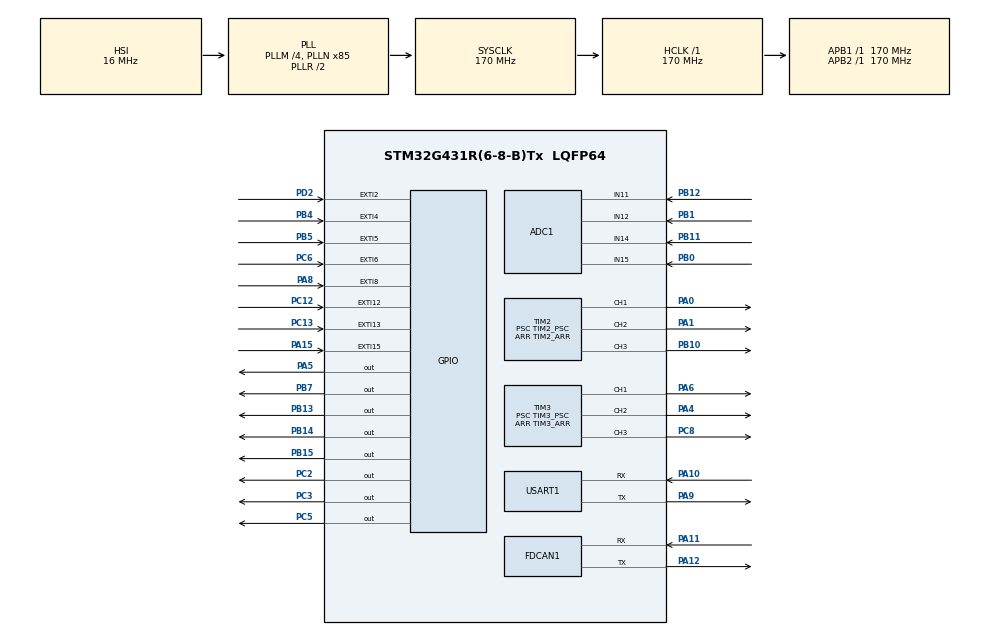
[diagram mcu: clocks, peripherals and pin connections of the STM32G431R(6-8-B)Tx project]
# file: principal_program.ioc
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ADC1.Channel-0\#ChannelRegularConversion=ADC_CHANNEL_11
ADC1.Channel-1\#ChannelRegularConversion=ADC_CHANNEL_12
ADC1.Channel-2\#ChannelRegularConversion=ADC_CHANNEL_14
ADC1.Channel-3\#ChannelRegularConversion=ADC_CHANNEL_15
ADC1.ContinuousConvMode=ENABLE
ADC1.DMAContinuousRequests=ENABLE
ADC1.NbrOfConversion=4
ADC1.NbrOfConversionFlag=1
ADC1.OffsetNumber-0\#ChannelRegularConversion=ADC_OFFSET_NONE
ADC1.OffsetNumber-1\#ChannelRegularConversion=ADC_OFFSET_NONE
ADC1.OffsetNumber-2\#ChannelRegularConversion=ADC_OFFSET_NONE
ADC1.OffsetNumber-3\#ChannelRegularConversion=ADC_OFFSET_NONE
ADC1.Rank-0\#ChannelRegularConversion=1
ADC1.Rank-1\#ChannelRegularConversion=2
ADC1.Rank-2\#ChannelRegularConversion=3
ADC1.Rank-3\#ChannelRegularConversion=4
ADC1.SamplingTime-0\#ChannelRegularConversion=ADC_SAMPLETIME_2CYCLES_5
ADC1.SamplingTime-1\#ChannelRegularConversion=ADC_SAMPLETIME_2CYCLES_5
ADC1.SamplingTime-2\#ChannelRegularConversion=ADC_SAMPLETIME_2CYCLES_5
ADC1.SamplingTime-3\#ChannelRegularConversion=ADC_SAMPLETIME_2CYCLES_5
ADC1.master=1
Dma.ADC1.0.Direction=DMA_PERIPH_TO_MEMORY
Dma.ADC1.0.EventEnable=DISABLE
Dma.ADC1.0.Instance=DMA1_Channel1
Dma.ADC1.0.MemDataAlignment=DMA_MDATAALIGN_HALFWORD
Dma.ADC1.0.MemInc=DMA_MINC_ENABLE
Dma.ADC1.0.Mode=DMA_CIRCULAR
Dma.ADC1.0.PeriphDataAlignment=DMA_PDATAALIGN_HALFWORD
Dma.ADC1.0.PeriphInc=DMA_PINC_DISABLE
Dma.ADC1.0.Polarity=HAL_DMAMUX_REQ_GEN_RISING
Dma.ADC1.0.Priority=DMA_PRIORITY_MEDIUM
Dma.ADC1.0.RequestNumber=1
Dma.ADC1.0.SignalID=NONE
Dma.ADC1.0.SyncEnable=DISABLE
Dma.ADC1.0.SyncPolarity=HAL_DMAMUX_SYNC_NO_EVENT
Dma.ADC1.0.SyncRequestNumber=1
Dma.ADC1.0.SyncSignalID=NONE
Dma.Request0=ADC1
Dma.Request1=USART1_TX
Dma.Request2=USART1_RX
Dma.USART1_RX.2.Direction=DMA_PERIPH_TO_MEMORY
Dma.USART1_RX.2.EventEnable=DISABLE
Dma.USART1_RX.2.Instance=DMA2_Channel2
Dma.USART1_RX.2.MemDataAlignment=DMA_MDATAALIGN_BYTE
Dma.USART1_RX.2.MemInc=DMA_MINC_ENABLE
Dma.USART1_RX.2.Mode=DMA_NORMAL
Dma.USART1_RX.2.PeriphDataAlignment=DMA_PDATAALIGN_BYTE
Dma.USART1_RX.2.PeriphInc=DMA_PINC_DISABLE
Dma.USART1_RX.2.Polarity=HAL_DMAMUX_REQ_GEN_RISING
Dma.USART1_RX.2.Priority=DMA_PRIORITY_LOW
Dma.USART1_RX.2.RequestNumber=1
Dma.USART1_RX.2.SignalID=NONE
Dma.USART1_RX.2.SyncEnable=DISABLE
Dma.USART1_RX.2.SyncPolarity=HAL_DMAMUX_SYNC_NO_EVENT
Dma.USART1_RX.2.SyncRequestNumber=1
Dma.USART1_RX.2.SyncSignalID=NONE
Dma.USART1_TX.1.Direction=DMA_MEMORY_TO_PERIPH
Dma.USART1_TX.1.EventEnable=DISABLE
Dma.USART1_TX.1.Instance=DMA2_Channel1
Dma.USART1_TX.1.MemDataAlignment=DMA_MDATAALIGN_BYTE
Dma.USART1_TX.1.MemInc=DMA_MINC_ENABLE
Dma.USART1_TX.1.Mode=DMA_NORMAL
Dma.USART1_TX.1.PeriphDataAlignment=DMA_PDATAALIGN_BYTE
Dma.USART1_TX.1.PeriphInc=DMA_PINC_DISABLE
Dma.USART1_TX.1.Polarity=HAL_DMAMUX_REQ_GEN_RISING
Dma.USART1_TX.1.Priority=DMA_PRIORITY_LOW
Dma.USART1_TX.1.RequestNumber=1
Dma.USART1_TX.1.SignalID=NONE
Dma.USART1_TX.1.SyncEnable=DISABLE
Dma.USART1_TX.1.SyncPolarity=HAL_DMAMUX_SYNC_NO_EVENT
Dma.USART1_TX.1.SyncRequestNumber=1
Dma.USART1_TX.1.SyncSignalID=NONE
FDCAN1.CalculateBaudRateNominal=499999
FDCAN1.CalculateTimeBitNominal=2000
FDCAN1.CalculateTimeQuantumNominal=117.64705882352942
FDCAN1.DataPrescaler=2
FDCAN1.DataTimeSeg1=14
FDCAN1.DataTimeSeg2=2
FDCAN1.FrameFormat=FDCAN_FRAME_CLASSIC
FDCAN1.Mode=FDCAN_MODE_NORMAL
FDCAN1.NominalPrescaler=20
FDCAN1.NominalTimeSeg1=14
FDCAN1.ProtocolException=ENABLE
FDCAN1.StdFiltersNbr=FDCAN_FILTER_COUNT
FDCAN1.TransmitPause=ENABLE
FREERTOS.Tasks01=defaultTask,24,256,StartDefaultTask,As weak,NULL,Dynamic,NULL,NULL;UartTask,40,256,StartUartTask,As weak,NULL,Dynamic,NULL,NULL;MotorTask,51,128,StartMotorTask,As weak,NULL,Dynamic,NULL,NULL;FdCanTask,41,256,StartFdCanTask,As weak,NULL,Dynamic,NULL,NULL;VehicleUpdateTa,49,128,StartVehicleUpdateTask,As weak,NULL,Dynamic,NULL,NULL;AdcTask,50,128,StartAdcTask,As weak,NULL,Dynamic,NULL,NULL;VehicleTask,48,256,StartVehicleTask,As weak,NULL,Dynamic,NULL,NULL
FREERTOS.configENABLE_BACKWARD_COMPATIBILITY=0
FREERTOS.configTOTAL_HEAP_SIZE=8192
FREERTOS.configUSE_NEWLIB_REENTRANT=1
Mcu.Family=STM32G4
Mcu.Name=STM32G431R(6-8-B)Tx
Mcu.Package=LQFP64
NUCLEO-G431RB.BUTTON=1
NUCLEO-G431RB.LD1=true
NUCLEO-G431RB.VCP=true
NVIC.DMA1_Channel1_IRQn=true\:5\:0\:false\:false\:true\:true\:false\:true\:true
NVIC.DMA2_Channel1_IRQn=true\:5\:0\:false\:false\:true\:false\:false\:true\:true
NVIC.DMA2_Channel2_IRQn=true\:5\:0\:false\:false\:true\:false\:false\:true\:true
NVIC.EXTI15_10_IRQn=true\:5\:0\:false\:false\:true\:true\:false\:true\:true
NVIC.EXTI2_IRQn=true\:5\:0\:false\:false\:true\:true\:true\:true\:true
NVIC.EXTI4_IRQn=true\:5\:0\:false\:false\:true\:true\:true\:true\:true
NVIC.EXTI9_5_IRQn=true\:5\:0\:false\:false\:true\:true\:true\:true\:true
NVIC.FDCAN1_IT0_IRQn=true\:5\:0\:false\:false\:true\:true\:true\:true\:true
NVIC.FDCAN1_IT1_IRQn=true\:5\:0\:false\:false\:true\:true\:true\:true\:true
NVIC.PriorityGroup=NVIC_PRIORITYGROUP_4
NVIC.TIM1_UP_TIM16_IRQn=true\:5\:0\:false\:false\:true\:true\:true\:true\:true
NVIC.TIM2_IRQn=true\:5\:0\:false\:false\:true\:true\:true\:true\:true
NVIC.TIM3_IRQn=true\:5\:0\:false\:false\:true\:true\:true\:true\:true
NVIC.TIM4_IRQn=true\:5\:0\:false\:false\:true\:true\:true\:true\:true
NVIC.TIM6_DAC_IRQn=true\:15\:0\:false\:false\:true\:false\:false\:true\:true
NVIC.TimeBase=TIM6_DAC_IRQn
NVIC.TimeBaseIP=TIM6
PA0.Signal=S_TIM2_CH1
PA1.Signal=S_TIM2_CH2
PA10.Mode=Asynchronous
PA10.Signal=USART1_RX
PA11.Mode=FDCAN_Activate
PA11.Signal=FDCAN1_RX
PA12.Mode=FDCAN_Activate
PA12.Signal=FDCAN1_TX
PA13.GPIO_Label=T_SWDIO
PA13.Signal=SYS_JTMS-SWDIO
PA14.GPIO_Label=T_SWCLK
PA14.Signal=SYS_JTCK-SWCLK
PA15.GPIO_ModeDefaultEXTI=GPIO_MODE_IT_RISING_FALLING
PA15.GPIO_PuPd=GPIO_NOPULL
PA15.Signal=GPXTI15
PA2.Signal=LPUART1_TX
PA3.Signal=LPUART1_RX
PA4.Signal=S_TIM3_CH2
PA5.Signal=GPIO_Output
PA6.Signal=S_TIM3_CH1
PA8.GPIO_ModeDefaultEXTI=GPIO_MODE_IT_RISING_FALLING
PA8.GPIO_PuPd=GPIO_NOPULL
PA8.Signal=GPXTI8
PA9.Mode=Asynchronous
PA9.Signal=USART1_TX
PB0.Mode=IN15-Single-Ended
PB0.Signal=ADC1_IN15
PB1.Mode=IN12-Single-Ended
PB1.Signal=ADC1_IN12
PB10.Signal=S_TIM2_CH3
PB11.Mode=IN14-Single-Ended
PB11.Signal=ADC1_IN14
PB12.Mode=IN11-Single-Ended
PB12.Signal=ADC1_IN11
PB13.GPIO_PuPd=GPIO_NOPULL
PB13.Signal=GPIO_Output
PB14.GPIO_PuPd=GPIO_NOPULL
PB14.Signal=GPIO_Output
PB15.GPIO_PuPd=GPIO_NOPULL
PB15.Signal=GPIO_Output
PB3.GPIO_Label=T_SWO
PB3.Signal=SYS_JTDO-SWO
PB4.GPIO_ModeDefaultEXTI=GPIO_MODE_IT_RISING_FALLING
PB4.GPIO_PuPd=GPIO_NOPULL
PB4.Signal=GPXTI4
PB5.GPIO_ModeDefaultEXTI=GPIO_MODE_IT_RISING_FALLING
PB5.GPIO_PuPd=GPIO_NOPULL
PB5.Signal=GPXTI5
PB7.GPIO_PuPd=GPIO_NOPULL
PB7.Signal=GPIO_Output
PC12.GPIO_ModeDefaultEXTI=GPIO_MODE_IT_RISING_FALLING
PC12.GPIO_PuPd=GPIO_NOPULL
PC12.Signal=GPXTI12
PC13.Signal=GPXTI13
PC14-OSC32_IN.GPIO_Label=RCC_OSC32_OUT
PC14-OSC32_IN.Signal=RCC_OSC32_IN
PC15-OSC32_OUT.GPIO_Label=RCC_OSC32_OUT
PC15-OSC32_OUT.Signal=RCC_OSC32_OUT
PC2.GPIO_PuPd=GPIO_NOPULL
PC2.Signal=GPIO_Output
PC3.GPIO_PuPd=GPIO_NOPULL
PC3.Signal=GPIO_Output
PC5.Signal=GPIO_Output
PC6.GPIO_ModeDefaultEXTI=GPIO_MODE_IT_FALLING
PC6.Signal=GPXTI6
PC8.Signal=S_TIM3_CH3
PD2.GPIO_ModeDefaultEXTI=GPIO_MODE_IT_RISING_FALLING
PD2.GPIO_PuPd=GPIO_NOPULL
PD2.Signal=GPXTI2
PF0-OSC_IN.GPIO_Label=RCC_OSC_IN
PF0-OSC_IN.Signal=RCC_OSC_IN
PF1-OSC_OUT.GPIO_Label=RCC_OSC_OUT
PF1-OSC_OUT.Signal=RCC_OSC_OUT
ProjectManager.HeapSize=0x200
ProjectManager.StackSize=0x400
ProjectManager.TargetToolchain=STM32CubeIDE
RCC.ADC12Freq_Value=170000000
RCC.AHBFreq_Value=170000000
RCC.APB1Freq_Value=170000000
RCC.APB1TimFreq_Value=170000000
RCC.APB2Freq_Value=170000000
RCC.APB2TimFreq_Value=170000000
RCC.CortexFreq_Value=170000000
RCC.EXTERNAL_CLOCK_VALUE=12288000
RCC.HCLKFreq_Value=170000000
RCC.HSE_VALUE=24000000
RCC.HSI48_VALUE=48000000
RCC.HSI_VALUE=16000000
RCC.LSE_VALUE=32768
RCC.PLLM=RCC_PLLM_DIV4
RCC.PLLN=85
RCC.RTCClockSelection=RCC_RTCCLKSOURCE_LSE
RCC.SYSCLKFreq_VALUE=170000000
RCC.SYSCLKSource=RCC_SYSCLKSOURCE_PLLCLK
RCC.USBFreq_Value=170000000
RCC.VCOOutputFreq_Value=340000000
SH.S_TIM2_CH1.0=TIM2_CH1,PWM Generation1 CH1
SH.S_TIM2_CH2.0=TIM2_CH2,PWM Generation2 CH2
SH.S_TIM2_CH3.0=TIM2_CH3,PWM Generation3 CH3
SH.S_TIM3_CH1.0=TIM3_CH1,PWM Generation1 CH1
SH.S_TIM3_CH2.0=TIM3_CH2,PWM Generation2 CH2
SH.S_TIM3_CH3.0=TIM3_CH3,PWM Generation3 CH3
TIM1.Channel-Output\ Compare1\ No\ Output=TIM_CHANNEL_1
TIM1.PeriodNoDither=TIM1_ARR
TIM1.Prescaler=TIM1_PSC
TIM2.Channel-PWM\ Generation1\ CH1=TIM_CHANNEL_1
TIM2.Channel-PWM\ Generation2\ CH2=TIM_CHANNEL_2
TIM2.Channel-PWM\ Generation3\ CH3=TIM_CHANNEL_3
TIM2.OCMode_PWM-PWM\ Generation3\ CH3=TIM_OCMODE_PWM1
TIM2.PeriodNoDither=TIM2_ARR
TIM2.Prescaler=TIM2_PSC
TIM2.PulseNoDither_1=0
TIM2.PulseNoDither_2=0
TIM2.PulseNoDither_3=0
TIM3.Channel-PWM\ Generation1\ CH1=TIM_CHANNEL_1
TIM3.Channel-PWM\ Generation2\ CH2=TIM_CHANNEL_2
TIM3.Channel-PWM\ Generation3\ CH3=TIM_CHANNEL_3
TIM3.PeriodNoDither=TIM3_ARR
TIM3.Prescaler=TIM3_PSC
TIM3.PulseNoDither_1=0
TIM3.PulseNoDither_2=0
TIM3.PulseNoDither_3=0
TIM4.Channel-PWM\ Generation1\ No\ Output=TIM_CHANNEL_1
TIM4.PeriodNoDither=TIM4_ARR
TIM4.Prescaler=TIM4_PSC
TIM4.PulseNoDither_1=TIM4_CH1_CCR
USART1.BaudRate=UART_BAUDRATE
USART1.VirtualMode-Asynchronous=VM_ASYNC
VP_FREERTOS_VS_CMSIS_V2.Mode=CMSIS_V2
VP_NUCLEO-G431RB_VS_BSP_COMMON.Mode=COMMON
VP_SYS_VS_DBSignals.Mode=DisableDeadBatterySignals
VP_SYS_VS_tim6.Mode=TIM6
VP_TIM1_VS_no_output1.Mode=Output Compare1 No Output
VP_TIM4_VS_no_output1.Mode=PWM Generation1 No Output
board=NUCLEO-G431RB

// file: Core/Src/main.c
/* USER CODE BEGIN Header */
/**
  ******************************************************************************
  * @file           : main.c
  * @brief          : Main program body
  ******************************************************************************
  * @attention
  *
  * Copyright (c) 2025 STMicroelectronics.
  * All rights reserved.
  *
  * This software is licensed under terms that can be found in the LICENSE file
  * in the root directory of this software component.
  * If no LICENSE file comes with this software, it is provided AS-IS.
  *
  ******************************************************************************
  */
/* USER CODE END Header */
#include "main.h"
#include "cmsis_os.h"
#include "adc.h"
#include "dma.h"
#include "fdcan.h"
#include "tim.h"
#include "usart.h"
#include "gpio.h"

/* USER CODE BEGIN Includes */
#include "main/main.h"
/* USER CODE END Includes */

COM_InitTypeDef BspCOMInit;

void SystemClock_Config(void);
void MX_FREERTOS_Init(void);

int main(void)
{

  /* MCU Configuration--------------------------------------------------------*/

  /* Reset of all peripherals, Initializes the Flash interface and the Systick. */
  HAL_Init();

  /* Configure the system clock */
  SystemClock_Config();

  /* Initialize all configured peripherals */
  MX_GPIO_Init();
  MX_DMA_Init();
  MX_TIM2_Init();
  MX_TIM1_Init();
  MX_ADC1_Init();
  MX_TIM3_Init();
  MX_FDCAN1_Init();
  MX_USART1_UART_Init();
  MX_TIM4_Init();

  /* Init scheduler */
  osKernelInitialize();

  /* Call init function for freertos objects (in cmsis_os2.c) */
  MX_FREERTOS_Init();

  /* Initialize leds */
  BSP_LED_Init(LED_GREEN);

  /* Initialize USER push-button, will be used to trigger an interrupt each time it's pressed.*/
  BSP_PB_Init(BUTTON_USER, BUTTON_MODE_EXTI);

  /* Initialize COM1 port (115200, 8 bits (7-bit data + 1 stop bit), no parity */
  BspCOMInit.BaudRate   = 115200;
  BspCOMInit.WordLength = COM_WORDLENGTH_8B;
  BspCOMInit.StopBits   = COM_STOPBITS_1;
  BspCOMInit.Parity     = COM_PARITY_NONE;
  BspCOMInit.HwFlowCtl  = COM_HWCONTROL_NONE;
  if (BSP_COM_Init(COM1, &BspCOMInit) != BSP_ERROR_NONE)
  {
    Error_Handler();
  }

  /* Start scheduler */
  osKernelStart();

  /* We should never get here as control is now taken by the scheduler */

  /* Infinite loop */
  while (1)
  {

  }
}

void SystemClock_Config(void)
{
  RCC_OscInitTypeDef RCC_OscInitStruct = {0};
  RCC_ClkInitTypeDef RCC_ClkInitStruct = {0};

  /** Configure the main internal regulator output voltage
  */
  HAL_PWREx_ControlVoltageScaling(PWR_REGULATOR_VOLTAGE_SCALE1_BOOST);

  /** Initializes the RCC Oscillators according to the specified parameters
  * in the RCC_OscInitTypeDef structure.
  */
  RCC_OscInitStruct.OscillatorType = RCC_OSCILLATORTYPE_HSI;
  RCC_OscInitStruct.HSIState = RCC_HSI_ON;
  RCC_OscInitStruct.HSICalibrationValue = RCC_HSICALIBRATION_DEFAULT;
  RCC_OscInitStruct.PLL.PLLState = RCC_PLL_ON;
  RCC_OscInitStruct.PLL.PLLSource = RCC_PLLSOURCE_HSI;
  RCC_OscInitStruct.PLL.PLLM = RCC_PLLM_DIV4;
  RCC_OscInitStruct.PLL.PLLN = 85;
  RCC_OscInitStruct.PLL.PLLP = RCC_PLLP_DIV2;
  RCC_OscInitStruct.PLL.PLLQ = RCC_PLLQ_DIV2;
  RCC_OscInitStruct.PLL.PLLR = RCC_PLLR_DIV2;
  if (HAL_RCC_OscConfig(&RCC_OscInitStruct) != HAL_OK)
  {
    Error_Handler();
  }

  /** Initializes the CPU, AHB and APB buses clocks
  */
  RCC_ClkInitStruct.ClockType = RCC_CLOCKTYPE_HCLK|RCC_CLOCKTYPE_SYSCLK
                              |RCC_CLOCKTYPE_PCLK1|RCC_CLOCKTYPE_PCLK2;
  RCC_ClkInitStruct.SYSCLKSource = RCC_SYSCLKSOURCE_PLLCLK;
  RCC_ClkInitStruct.AHBCLKDivider = RCC_SYSCLK_DIV1;
  RCC_ClkInitStruct.APB1CLKDivider = RCC_HCLK_DIV1;
  RCC_ClkInitStruct.APB2CLKDivider = RCC_HCLK_DIV1;

  if (HAL_RCC_ClockConfig(&RCC_ClkInitStruct, FLASH_LATENCY_4) != HAL_OK)
  {
    Error_Handler();
  }
}

void HAL_TIM_PeriodElapsedCallback(TIM_HandleTypeDef *htim)
{
  if (htim->Instance == TIM6) {
    HAL_IncTick();
  }
  /* USER CODE BEGIN Callback 1 */
  USER_HAL_TIM_PeriodElapsedCallback(htim);
  /* USER CODE END Callback 1 */
}

void Error_Handler(void)
{
  __disable_irq();
  while (1)
  {
  }
}

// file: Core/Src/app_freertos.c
/* USER CODE BEGIN Header */
/**
  ******************************************************************************
  * File Name          : app_freertos.c
  * Description        : Code for freertos applications
  ******************************************************************************
  * @attention
  *
  * Copyright (c) 2025 STMicroelectronics.
  * All rights reserved.
  *
  * This software is licensed under terms that can be found in the LICENSE file
  * in the root directory of this software component.
  * If no LICENSE file comes with this software, it is provided AS-IS.
  *
  ******************************************************************************
  */
/* USER CODE END Header */

#include "FreeRTOS.h"
#include "task.h"
#include "main.h"
#include "cmsis_os.h"

/* USER CODE BEGIN Includes */
#include "main/config.h"
/* USER CODE END Includes */

/* Definitions for defaultTask */
osThreadId_t defaultTaskHandle;
const osThreadAttr_t defaultTask_attributes = {
  .name = "defaultTask",
  .priority = (osPriority_t) osPriorityNormal,
  .stack_size = 256 * 4
};
/* Definitions for UartTask */
osThreadId_t UartTaskHandle;
const osThreadAttr_t UartTask_attributes = {
  .name = "UartTask",
  .priority = (osPriority_t) osPriorityHigh,
  .stack_size = 256 * 4
};
/* Definitions for MotorTask */
osThreadId_t MotorTaskHandle;
const osThreadAttr_t MotorTask_attributes = {
  .name = "MotorTask",
  .priority = (osPriority_t) osPriorityRealtime3,
  .stack_size = 128 * 4
};
/* Definitions for FdCanTask */
osThreadId_t FdCanTaskHandle;
const osThreadAttr_t FdCanTask_attributes = {
  .name = "FdCanTask",
  .priority = (osPriority_t) osPriorityHigh1,
  .stack_size = 256 * 4
};
/* Definitions for VehicleUpdateTa */
osThreadId_t VehicleUpdateTaHandle;
const osThreadAttr_t VehicleUpdateTa_attributes = {
  .name = "VehicleUpdateTa",
  .priority = (osPriority_t) osPriorityRealtime1,
  .stack_size = 128 * 4
};
/* Definitions for AdcTask */
osThreadId_t AdcTaskHandle;
const osThreadAttr_t AdcTask_attributes = {
  .name = "AdcTask",
  .priority = (osPriority_t) osPriorityRealtime2,
  .stack_size = 128 * 4
};
/* Definitions for VehicleTask */
osThreadId_t VehicleTaskHandle;
const osThreadAttr_t VehicleTask_attributes = {
  .name = "VehicleTask",
  .priority = (osPriority_t) osPriorityRealtime,
  .stack_size = 256 * 4
};

void StartDefaultTask(void *argument);
void StartUartTask(void *argument);
void StartMotorTask(void *argument);
void StartFdCanTask(void *argument);
void StartVehicleUpdateTask(void *argument);
void StartAdcTask(void *argument);
void StartVehicleTask(void *argument);

void MX_FREERTOS_Init(void); /* (MISRA C 2004 rule 8.1) */

void MX_FREERTOS_Init(void) {

  /* Create the thread(s) */
  /* creation of defaultTask */
  defaultTaskHandle = osThreadNew(StartDefaultTask, NULL, &defaultTask_attributes);

  /* creation of UartTask */
  UartTaskHandle = osThreadNew(StartUartTask, NULL, &UartTask_attributes);

  /* creation of MotorTask */
  MotorTaskHandle = osThreadNew(StartMotorTask, NULL, &MotorTask_attributes);

  /* creation of FdCanTask */
  FdCanTaskHandle = osThreadNew(StartFdCanTask, NULL, &FdCanTask_attributes);

  /* creation of VehicleUpdateTa */
  VehicleUpdateTaHandle = osThreadNew(StartVehicleUpdateTask, NULL, &VehicleUpdateTa_attributes);

  /* creation of AdcTask */
  AdcTaskHandle = osThreadNew(StartAdcTask, NULL, &AdcTask_attributes);

  /* creation of VehicleTask */
  VehicleTaskHandle = osThreadNew(StartVehicleTask, NULL, &VehicleTask_attributes);

}

__weak void StartDefaultTask(void *argument)
{
  for(;;)
  {
    osDelay(1);
  }
}

__weak void StartUartTask(void *argument)
{
  for(;;)
  {
    osDelay(1);
  }
}

__weak void StartMotorTask(void *argument)
{
  for(;;)
  {
    osDelay(1);
  }
}

__weak void StartFdCanTask(void *argument)
{
  for(;;)
  {
    osDelay(1);
  }
}

__weak void StartVehicleUpdateTask(void *argument)
{
  for(;;)
  {
    osDelay(1);
  }
}

__weak void StartAdcTask(void *argument)
{
  for(;;)
  {
    osDelay(1);
  }
}

__weak void StartVehicleTask(void *argument)
{
  for(;;)
  {
    osDelay(1);
  }
}
